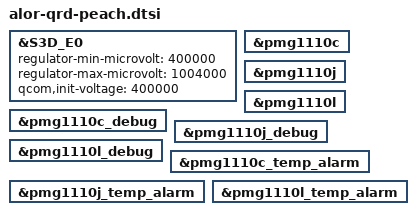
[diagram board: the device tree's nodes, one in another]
// SPDX-License-Identifier: BSD-3-Clause
/*
 * Copyright (c) Qualcomm Technologies, Inc. and/or its subsidiaries.
 */

#include "alor-qrd.dtsi"

&S3D_E0 {
	regulator-min-microvolt = <400000>;
	regulator-max-microvolt = <1004000>;
	qcom,init-voltage = <400000>;
};

&pmg1110c {
	status = "ok";
};

&pmg1110j {
	status = "ok";
};

&pmg1110l {
	status = "ok";
};

&pmg1110c_debug {
	status = "ok";
};

&pmg1110j_debug {
	status = "ok";
};

&pmg1110l_debug {
	status = "ok";
};

&pmg1110c_temp_alarm {
	status = "ok";
};

&pmg1110j_temp_alarm {
	status = "ok";
};

&pmg1110l_temp_alarm {
	status = "ok";
};
